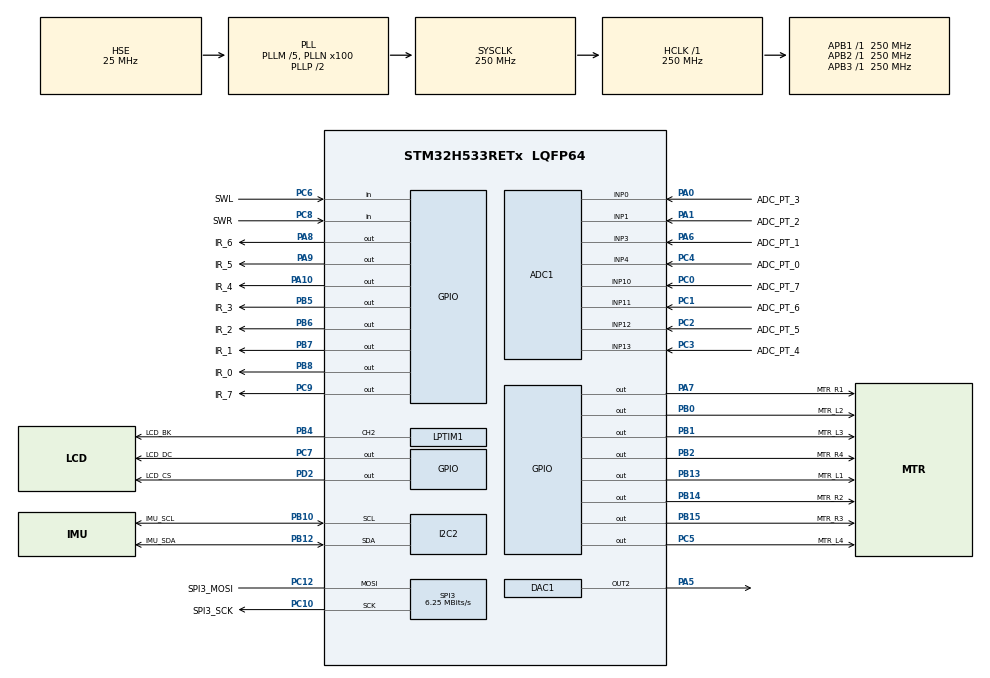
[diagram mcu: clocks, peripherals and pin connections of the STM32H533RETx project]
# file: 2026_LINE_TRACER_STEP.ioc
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ADC1.Channel-0\#ChannelRegularConversion=ADC_CHANNEL_4
ADC1.Channel-1\#ChannelRegularConversion=ADC_CHANNEL_3
ADC1.Channel-2\#ChannelRegularConversion=ADC_CHANNEL_1
ADC1.Channel-3\#ChannelRegularConversion=ADC_CHANNEL_0
ADC1.Channel-4\#ChannelRegularConversion=ADC_CHANNEL_13
ADC1.Channel-5\#ChannelRegularConversion=ADC_CHANNEL_12
ADC1.Channel-6\#ChannelRegularConversion=ADC_CHANNEL_11
ADC1.Channel-7\#ChannelRegularConversion=ADC_CHANNEL_10
ADC1.ClockPrescaler=ADC_CLOCK_ASYNC_DIV8
ADC1.DiscontinuousConvMode=ENABLE
ADC1.ExternalTrigConv=ADC_EXTERNALTRIG_T3_TRGO
ADC1.MonitoredBy-0\#ChannelRegularConversion=__NULL
ADC1.MonitoredBy-1\#ChannelRegularConversion=__NULL
ADC1.MonitoredBy-2\#ChannelRegularConversion=__NULL
ADC1.MonitoredBy-3\#ChannelRegularConversion=__NULL
ADC1.MonitoredBy-4\#ChannelRegularConversion=__NULL
ADC1.MonitoredBy-5\#ChannelRegularConversion=__NULL
ADC1.MonitoredBy-6\#ChannelRegularConversion=__NULL
ADC1.MonitoredBy-7\#ChannelRegularConversion=__NULL
ADC1.NbrOfConversion=8
ADC1.NbrOfConversionFlag=1
ADC1.OffsetNumber-0\#ChannelRegularConversion=ADC_OFFSET_NONE
ADC1.OffsetNumber-1\#ChannelRegularConversion=ADC_OFFSET_NONE
ADC1.OffsetNumber-2\#ChannelRegularConversion=ADC_OFFSET_NONE
ADC1.OffsetNumber-3\#ChannelRegularConversion=ADC_OFFSET_NONE
ADC1.OffsetNumber-4\#ChannelRegularConversion=ADC_OFFSET_NONE
ADC1.OffsetNumber-5\#ChannelRegularConversion=ADC_OFFSET_NONE
ADC1.OffsetNumber-6\#ChannelRegularConversion=ADC_OFFSET_NONE
ADC1.OffsetNumber-7\#ChannelRegularConversion=ADC_OFFSET_NONE
ADC1.OversamplingMode=ENABLE
ADC1.Rank-0\#ChannelRegularConversion=1
ADC1.Rank-1\#ChannelRegularConversion=2
ADC1.Rank-2\#ChannelRegularConversion=3
ADC1.Rank-3\#ChannelRegularConversion=4
ADC1.Rank-4\#ChannelRegularConversion=5
ADC1.Rank-5\#ChannelRegularConversion=6
ADC1.Rank-6\#ChannelRegularConversion=7
ADC1.Rank-7\#ChannelRegularConversion=8
ADC1.Ratio=ADC_OVERSAMPLING_RATIO_4
ADC1.RightBitShift=ADC_RIGHTBITSHIFT_NONE
ADC1.SamplingTime-0\#ChannelRegularConversion=ADC_SAMPLETIME_247CYCLES_5
ADC1.SamplingTime-1\#ChannelRegularConversion=ADC_SAMPLETIME_247CYCLES_5
ADC1.SamplingTime-2\#ChannelRegularConversion=ADC_SAMPLETIME_247CYCLES_5
ADC1.SamplingTime-3\#ChannelRegularConversion=ADC_SAMPLETIME_247CYCLES_5
ADC1.SamplingTime-4\#ChannelRegularConversion=ADC_SAMPLETIME_247CYCLES_5
ADC1.SamplingTime-5\#ChannelRegularConversion=ADC_SAMPLETIME_247CYCLES_5
ADC1.SamplingTime-6\#ChannelRegularConversion=ADC_SAMPLETIME_247CYCLES_5
ADC1.SamplingTime-7\#ChannelRegularConversion=ADC_SAMPLETIME_247CYCLES_5
ADC1.master=1
BOOTPATH.BootPathName=LEGACY
BOOTPATH.UserSelectedBootPath=LEGACY
CORTEX_M33_NS.userName=CORTEX_M33
DAC1.DAC_Channel-DAC_OUT2_Ext=DAC_CHANNEL_2
I2C2.Timing=0x60808CD3
LPTIM1.ClockPrescaler=LPTIM_PRESCALER_DIV128
LPTIM1.Period=1000-1
Mcu.Family=STM32H5
Mcu.Name=STM32H533RETx
Mcu.Package=LQFP64
NUCLEO-H533RE.BUTTON=2
NUCLEO-H533RE.LD4=false
NUCLEO-H533RE.VCP=true
NVIC.ADC1_IRQn=true\:1\:0\:false\:false\:true\:true\:true\:true
NVIC.PriorityGroup=NVIC_PRIORITYGROUP_4
NVIC.TIM1_UP_IRQn=true\:0\:0\:false\:false\:true\:true\:true\:true
NVIC.TIM3_IRQn=true\:0\:0\:false\:false\:true\:true\:true\:true
NVIC.TIM6_IRQn=true\:1\:0\:false\:false\:true\:true\:true\:true
NVIC.TIM7_IRQn=true\:2\:0\:false\:false\:true\:true\:true\:true
NVIC.TIM8_UP_IRQn=true\:0\:0\:false\:false\:true\:true\:true\:true
PA0.GPIO_Label=ADC_PT_3
PA0.Signal=ADCx_INP0
PA1.GPIO_Label=ADC_PT_2
PA1.Signal=ADCx_INP1
PA10.GPIO_Label=IR_4
PA10.Signal=GPIO_Output
PA13(JTMS/SWDIO).GPIO_Label=SWDIO
PA13(JTMS/SWDIO).Signal=DEBUG_JTMS-SWDIO
PA14(JTCK/SWCLK).GPIO_Label=SWCLK
PA14(JTCK/SWCLK).Signal=DEBUG_JTCK-SWCLK
PA15(JTDI).GPIO_Label=JTDI
PA15(JTDI).Signal=DEBUG_JTDI
PA2.Signal=USART2_TX
PA3.Signal=USART2_RX
PA5.Signal=COMP_DAC12_group
PA6.GPIO_Label=ADC_PT_1
PA6.Signal=ADCx_INP3
PA7.GPIO_Label=MTR_R1
PA7.Signal=GPIO_Output
PA8.GPIO_Label=IR_6
PA8.Signal=GPIO_Output
PA9.GPIO_Label=IR_5
PA9.Signal=GPIO_Output
PB0.GPIO_Label=MTR_L2
PB0.Signal=GPIO_Output
PB1.GPIO_Label=MTR_L3
PB1.Signal=GPIO_Output
PB10.GPIO_Label=IMU_SCL
PB10.Mode=I2C
PB10.Signal=I2C2_SCL
PB12.GPIO_Label=IMU_SDA
PB12.Mode=I2C
PB12.Signal=I2C2_SDA
PB13.GPIO_Label=MTR_L1
PB13.Signal=GPIO_Output
PB14.GPIO_Label=MTR_R2
PB14.Signal=GPIO_Output
PB15.GPIO_Label=MTR_R3
PB15.Signal=GPIO_Output
PB2.GPIO_Label=MTR_R4
PB2.Signal=GPIO_Output
PB3(JTDO/TRACESWO).GPIO_Label=SWO
PB3(JTDO/TRACESWO).Signal=DEBUG_JTDO-SWO
PB4(NJTRST).GPIO_Label=LCD_BK
PB4(NJTRST).Signal=S_LPTIM1_CH2
PB5.GPIO_Label=IR_3
PB5.Signal=GPIO_Output
PB6.GPIO_Label=IR_2
PB6.Signal=GPIO_Output
PB7.GPIO_Label=IR_1
PB7.Signal=GPIO_Output
PB8.GPIO_Label=IR_0
PB8.Signal=GPIO_Output
PC0.GPIO_Label=ADC_PT_7
PC0.Signal=ADCx_INP10
PC1.GPIO_Label=ADC_PT_6
PC1.Signal=ADCx_INP11
PC10.GPIO_Label=SPI3_SCK
PC10.Mode=Simplex_Bidirectional_Master
PC10.Signal=SPI3_SCK
PC12.GPIO_Label=SPI3_MOSI
PC12.Mode=Simplex_Bidirectional_Master
PC12.Signal=SPI3_MOSI
PC14-OSC32_IN(OSC32_IN).Mode=LSE-External-Oscillator
PC14-OSC32_IN(OSC32_IN).Signal=RCC_OSC32_IN
PC15-OSC32_OUT(OSC32_OUT).Mode=LSE-External-Oscillator
PC15-OSC32_OUT(OSC32_OUT).Signal=RCC_OSC32_OUT
PC2.GPIO_Label=ADC_PT_5
PC2.Signal=ADCx_INP12
PC3.GPIO_Label=ADC_PT_4
PC3.Signal=ADCx_INP13
PC4.GPIO_Label=ADC_PT_0
PC4.Signal=ADCx_INP4
PC5.GPIO_Label=MTR_L4
PC5.Signal=GPIO_Output
PC6.GPIO_Label=SWL
PC6.GPIO_PuPd=GPIO_PULLUP
PC6.Signal=GPIO_Input
PC7.GPIO_Label=LCD_DC
PC7.Signal=GPIO_Output
PC8.GPIO_Label=SWR
PC8.GPIO_PuPd=GPIO_PULLUP
PC8.Signal=GPIO_Input
PC9.GPIO_Label=IR_7
PC9.Signal=GPIO_Output
PD2.GPIO_Label=LCD_CS
PD2.Signal=GPIO_Output
PH0-OSC_IN(PH0).Mode=HSE-External-Oscillator
PH0-OSC_IN(PH0).Signal=RCC_OSC_IN
PH1-OSC_OUT(PH1).Mode=HSE-External-Oscillator
PH1-OSC_OUT(PH1).Signal=RCC_OSC_OUT
ProjectManager.HeapSize=0x200
ProjectManager.StackSize=0x400
ProjectManager.TargetToolchain=STM32CubeIDE
RCC.ADCFreq_Value=250000000
RCC.AHBFreq_Value=250000000
RCC.APB1Freq_Value=250000000
RCC.APB1TimFreq_Value=250000000
RCC.APB2Freq_Value=250000000
RCC.APB2TimFreq_Value=250000000
RCC.APB3Freq_Value=250000000
RCC.CSI_VALUE=4000000
RCC.CortexFreq_Value=250000000
RCC.EPOD_VALUE=25000000
RCC.HCLKFreq_Value=250000000
RCC.HSE_VALUE=25000000
RCC.HSI48_VALUE=48000000
RCC.HSI_VALUE=64000000
RCC.LSIRC_VALUE=32000
RCC.PLL1Q=5
RCC.PLLFRACN=0
RCC.PLLM=5
RCC.PLLN=100
RCC.PLLSourceVirtual=RCC_PLL1_SOURCE_HSE
RCC.SYSCLKFreq_VALUE=250000000
RCC.SYSCLKSource=RCC_SYSCLKSOURCE_PLLCLK
RCC.USBFreq_Value=48000000
RCC.VCOOutputFreq_Value=500000000
SH.ADCx_INP0.0=ADC1_INP0,IN0-Single-Ended
SH.ADCx_INP1.0=ADC1_INP1,IN1-Single-Ended
SH.ADCx_INP10.0=ADC1_INP10,IN10-Single-Ended
SH.ADCx_INP11.0=ADC1_INP11,IN11-Single-Ended
SH.ADCx_INP12.0=ADC1_INP12,IN12-Single-Ended
SH.ADCx_INP13.0=ADC1_INP13,IN13-Single-Ended
SH.ADCx_INP3.0=ADC1_INP3,IN3-Single-Ended
SH.ADCx_INP4.0=ADC1_INP4,IN4-Single-Ended
SH.COMP_DAC12_group.0=DAC1_OUT2,DAC_OUT2_Ext
SH.S_LPTIM1_CH2.0=LPTIM1_CH2,OutputIO_CH2
SPI3.BaudRatePrescaler=SPI_BAUDRATEPRESCALER_16
SPI3.CalculateBaudRate=6.25 MBits/s
SPI3.DataSize=SPI_DATASIZE_8BIT
SPI3.Direction=SPI_DIRECTION_1LINE
SPI3.Mode=SPI_MODE_MASTER
SPI3.VirtualType=VM_MASTER
TIM1.AutoReloadPreload=TIM_AUTORELOAD_PRELOAD_ENABLE
TIM3.PeriodNoDither=40-1
TIM3.Prescaler=250-1
TIM3.TIM_MasterOutputTrigger=TIM_TRGO_UPDATE
TIM3.TIM_MasterSlaveMode=TIM_MASTERSLAVEMODE_ENABLE
TIM6.PeriodNoDither=125-1
TIM6.Prescaler=250-1
TIM6.TIM_MasterOutputTrigger=TIM_TRGO_UPDATE
TIM7.PeriodNoDither=500-1
TIM7.Prescaler=250-1
TIM8.AutoReloadPreload=TIM_AUTORELOAD_PRELOAD_ENABLE
VP_BOOTPATH_VS_BOOTPATH.Mode=BP_Activate
VP_CORTEX_M33_NS_VS_Hclk.Mode=Hclk_Mode
VP_ICACHE_VS_ICACHE.Mode=DefaultMode
VP_LPTIM1_VS_CH2.Mode=Channel_2_Active
VP_LPTIM1_VS_LPTIM_counterModeInternalClock.Mode=Counts__internal_clock_event_00
VP_MEMORYMAP_VS_MEMORYMAP.Mode=CurAppReg
VP_NUCLEO-H533RE_VS_BSP_COMMON.Mode=COMMON
VP_PWR_VS_LPOM.Mode=PowerOptimisation
VP_PWR_VS_SECSignals.Mode=Security/Privilege
VP_RNG_VS_RNG.Mode=RNG_Activate
VP_TIM12_VS_ClockSourceINT.Mode=Internal
VP_TIM1_VS_ClockSourceINT.Mode=Internal
VP_TIM3_VS_ClockSourceINT.Mode=Internal
VP_TIM3_VS_OPM.Mode=OPM_bit
VP_TIM6_VS_ClockSourceINT.Mode=Enable_Timer
VP_TIM7_VS_ClockSourceINT.Mode=Enable_Timer
VP_TIM8_VS_ClockSourceINT.Mode=Internal
board=NUCLEO-H533RE

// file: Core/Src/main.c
/* USER CODE BEGIN Header */
/**
 ******************************************************************************
 * @file           : main.c
 * @brief          : Main program body
 ******************************************************************************
 * @attention
 *
 * Copyright (c) 2026 STMicroelectronics.
 * All rights reserved.
 *
 * This software is licensed under terms that can be found in the LICENSE file
 * in the root directory of this software component.
 * If no LICENSE file comes with this software, it is provided AS-IS.
 *
 ******************************************************************************
 */
/* USER CODE END Header */
#include "main.h"
#include "adc.h"
#include "dac.h"
#include "i2c.h"
#include "icache.h"
#include "lptim.h"
#include "rng.h"
#include "spi.h"
#include "tim.h"
#include "gpio.h"

/* USER CODE BEGIN Includes */
#include "st7789_lcd.h"

#include "button.h"
#include "menu.h"
#include "sensor.h"
/* USER CODE END Includes */

COM_InitTypeDef BspCOMInit;

void SystemClock_Config(void);

int main(void)
{

  /* MCU Configuration--------------------------------------------------------*/

  /* Reset of all peripherals, Initializes the Flash interface and the Systick. */
  HAL_Init();

  /* Configure the system clock */
  SystemClock_Config();

  /* Initialize all configured peripherals */
  MX_GPIO_Init();
  MX_ADC1_Init();
  MX_I2C2_Init();
  MX_LPTIM1_Init();
  MX_SPI3_Init();
  MX_TIM3_Init();
  MX_ICACHE_Init();
  MX_RNG_Init();
  MX_TIM6_Init();
  MX_TIM7_Init();
  MX_TIM12_Init();
  MX_TIM1_Init();
  MX_TIM8_Init();
  MX_DAC1_Init();

  /* Initialize User push-button without interrupt mode. */
  BSP_PB_Init(BUTTON_USER, BUTTON_MODE_GPIO);

  /* Initialize COM1 port (115200, 8 bits (7-bit data + 1 stop bit), no parity */
  BspCOMInit.BaudRate   = 115200;
  BspCOMInit.WordLength = COM_WORDLENGTH_8B;
  BspCOMInit.StopBits   = COM_STOPBITS_1;
  BspCOMInit.Parity     = COM_PARITY_NONE;
  BspCOMInit.HwFlowCtl  = COM_HWCONTROL_NONE;
  if (BSP_COM_Init(COM1, &BspCOMInit) != BSP_ERROR_NONE)
  {
    Error_Handler();
  }

  /* Infinite loop */
  /* USER CODE BEGIN WHILE */
    MX_Button_Init(); // .ioc 재생성 방어: BSP_PB_Init 등 모든 초기화 끝난 직후 덮어쓰기

    while (1) {
		Main_Menu();

    /* USER CODE END WHILE */

	}
}

void SystemClock_Config(void)
{
  RCC_OscInitTypeDef RCC_OscInitStruct = {0};
  RCC_ClkInitTypeDef RCC_ClkInitStruct = {0};

  /** Configure the main internal regulator output voltage
  */
  __HAL_PWR_VOLTAGESCALING_CONFIG(PWR_REGULATOR_VOLTAGE_SCALE0);

  while(!__HAL_PWR_GET_FLAG(PWR_FLAG_VOSRDY)) {}

  /** Configure LSE Drive Capability
  *  Warning : Only applied when the LSE is disabled.
  */
  HAL_PWR_EnableBkUpAccess();
  __HAL_RCC_LSEDRIVE_CONFIG(RCC_LSEDRIVE_LOW);

  /** Initializes the RCC Oscillators according to the specified parameters
  * in the RCC_OscInitTypeDef structure.
  */
  RCC_OscInitStruct.OscillatorType = RCC_OSCILLATORTYPE_HSI48|RCC_OSCILLATORTYPE_HSE
                              |RCC_OSCILLATORTYPE_LSE;
  RCC_OscInitStruct.HSEState = RCC_HSE_ON;
  RCC_OscInitStruct.LSEState = RCC_LSE_ON;
  RCC_OscInitStruct.HSI48State = RCC_HSI48_ON;
  RCC_OscInitStruct.PLL.PLLState = RCC_PLL_ON;
  RCC_OscInitStruct.PLL.PLLSource = RCC_PLL1_SOURCE_HSE;
  RCC_OscInitStruct.PLL.PLLM = 5;
  RCC_OscInitStruct.PLL.PLLN = 100;
  RCC_OscInitStruct.PLL.PLLP = 2;
  RCC_OscInitStruct.PLL.PLLQ = 5;
  RCC_OscInitStruct.PLL.PLLR = 2;
  RCC_OscInitStruct.PLL.PLLRGE = RCC_PLL1_VCIRANGE_2;
  RCC_OscInitStruct.PLL.PLLVCOSEL = RCC_PLL1_VCORANGE_WIDE;
  RCC_OscInitStruct.PLL.PLLFRACN = 0;
  if (HAL_RCC_OscConfig(&RCC_OscInitStruct) != HAL_OK)
  {
    Error_Handler();
  }

  /** Initializes the CPU, AHB and APB buses clocks
  */
  RCC_ClkInitStruct.ClockType = RCC_CLOCKTYPE_HCLK|RCC_CLOCKTYPE_SYSCLK
                              |RCC_CLOCKTYPE_PCLK1|RCC_CLOCKTYPE_PCLK2
                              |RCC_CLOCKTYPE_PCLK3;
  RCC_ClkInitStruct.SYSCLKSource = RCC_SYSCLKSOURCE_PLLCLK;
  RCC_ClkInitStruct.AHBCLKDivider = RCC_SYSCLK_DIV1;
  RCC_ClkInitStruct.APB1CLKDivider = RCC_HCLK_DIV1;
  RCC_ClkInitStruct.APB2CLKDivider = RCC_HCLK_DIV1;
  RCC_ClkInitStruct.APB3CLKDivider = RCC_HCLK_DIV1;

  if (HAL_RCC_ClockConfig(&RCC_ClkInitStruct, FLASH_LATENCY_5) != HAL_OK)
  {
    Error_Handler();
  }

  /** Configure the programming delay
  */
  __HAL_FLASH_SET_PROGRAM_DELAY(FLASH_PROGRAMMING_DELAY_2);
}

void Error_Handler(void)
{
	__disable_irq();
	while (1) {
	}
}
